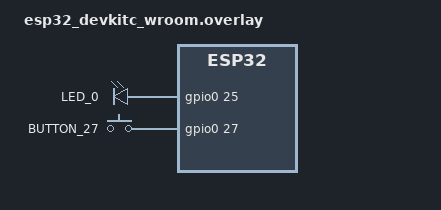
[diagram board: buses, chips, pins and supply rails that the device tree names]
/ {
	leds {
		compatible = "gpio-leds"; // This is the driver that will be used to control the LED
		blinking_led: blinking_led {  // This is the name of the LED
			gpios = <&gpio0 25 GPIO_ACTIVE_HIGH>; // This is the GPIO pin that the LED is connected to
			label = "LED_0"; // This is the label that will be used to control the LED
		};
	};

	buttons {
		compatible = "gpio-keys"; // This is the driver that will be used to control the button
		// debounce-interval-ms = <50>; // This is the debounce interval for the button
		push_button: push_button { // This is the name of the button
			gpios = <&gpio0 27 (GPIO_ACTIVE_HIGH)>; // This is the GPIO pin that the button is connected to
			label = "BUTTON_27";
		};
	};
};
